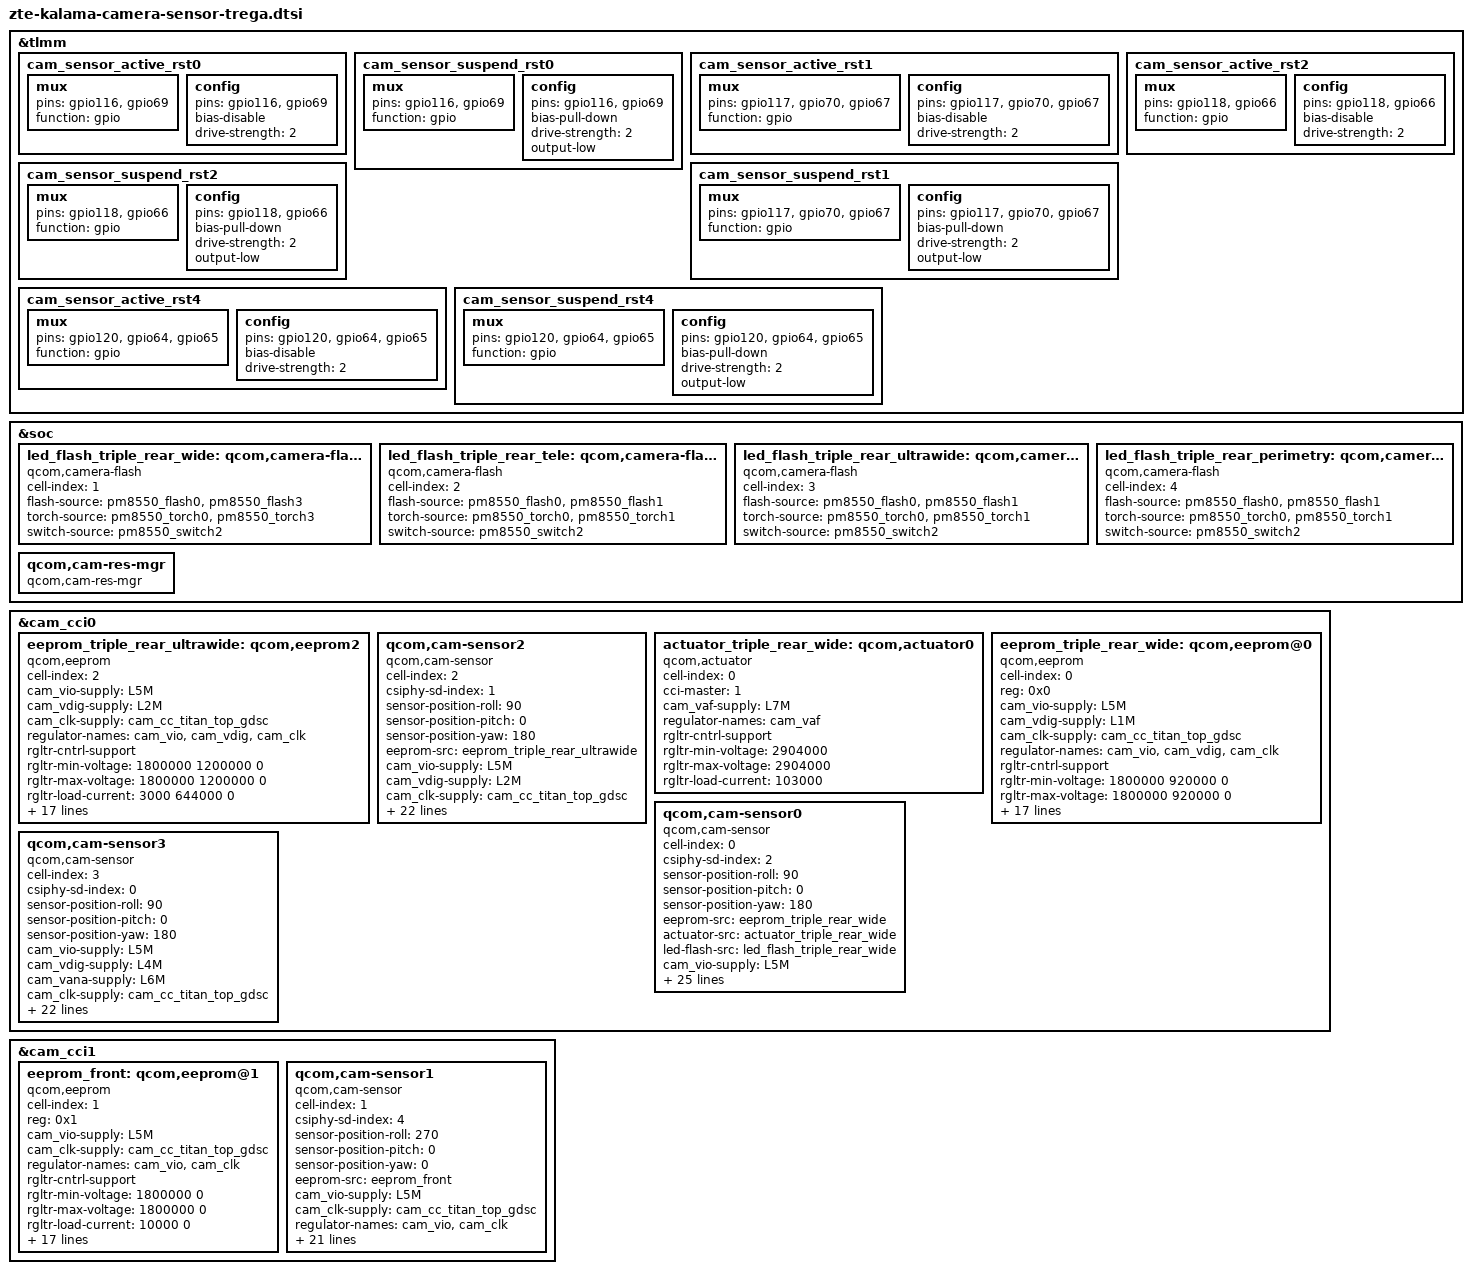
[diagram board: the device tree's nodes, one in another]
#include <dt-bindings/msm-camera.h>
&tlmm {
	cam_sensor_active_rst0: cam_sensor_active_rst0 {
		/* RESET 2 */
		mux {
			pins = "gpio116", "gpio69";
			function = "gpio";
		};

		config {
			pins = "gpio116", "gpio69";
			bias-disable; /* No PULL */
			drive-strength = <2>; /* 2 MA */
		};
	};

	cam_sensor_suspend_rst0: cam_sensor_suspend_rst0 {
		/* RESET 2 */
		mux {
			pins = "gpio116", "gpio69";
			function = "gpio";
		};

		config {
			pins = "gpio116", "gpio69";
			bias-pull-down; /* PULL DOWN */
			drive-strength = <2>; /* 2 MA */
			output-low;
		};
	};

	cam_sensor_active_rst1: cam_sensor_active_rst1 {
		/* RESET 2 */
		mux {
			pins = "gpio117", "gpio70", "gpio67";
			function = "gpio";
		};

		config {
			pins = "gpio117", "gpio70", "gpio67";
			bias-disable; /* No PULL */
			drive-strength = <2>; /* 2 MA */
		};
	};

	cam_sensor_suspend_rst1: cam_sensor_suspend_rst1 {
		/* RESET 2 */
		mux {
			pins = "gpio117", "gpio70", "gpio67";
			function = "gpio";
		};

		config {
			pins = "gpio117", "gpio70", "gpio67";
			bias-pull-down; /* PULL DOWN */
			drive-strength = <2>; /* 2 MA */
			output-low;
		};
	};

	cam_sensor_active_rst2: cam_sensor_active_rst2 {
		/* RESET 2 */
		mux {
			pins = "gpio118", "gpio66";
			function = "gpio";
		};

		config {
			pins = "gpio118", "gpio66";
			bias-disable; /* No PULL */
			drive-strength = <2>; /* 2 MA */
		};
	};

	cam_sensor_suspend_rst2: cam_sensor_suspend_rst2 {
		/* RESET 2 */
		mux {
			pins = "gpio118", "gpio66";
			function = "gpio";
		};

		config {
			pins = "gpio118", "gpio66";
			bias-pull-down; /* PULL DOWN */
			drive-strength = <2>; /* 2 MA */
			output-low;
		};
	};

	cam_sensor_active_rst4: cam_sensor_active_rst4 {
		/* RESET 3 */
		mux {
			pins = "gpio120", "gpio64", "gpio65";
			function = "gpio";
		};

		config {
			pins = "gpio120", "gpio64", "gpio65";
			bias-disable; /* No PULL */
			drive-strength = <2>; /* 2 MA */
		};
	};

	cam_sensor_suspend_rst4: cam_sensor_suspend_rst4 {
		/* RESET 3 */
		mux {
			pins = "gpio120", "gpio64", "gpio65";
			function = "gpio";
		};

		config {
			pins = "gpio120", "gpio64", "gpio65";
			bias-pull-down; /* PULL DOWN */
			drive-strength = <2>; /* 2 MA */
			output-low;
		};
	};
};

&soc {
	led_flash_triple_rear_wide: qcom,camera-flash1 {
		cell-index = <1>;
		compatible = "qcom,camera-flash";
		flash-source = <&pm8550_flash0 &pm8550_flash3>;
		torch-source = <&pm8550_torch0 &pm8550_torch3>;
		switch-source = <&pm8550_switch2>;
		status = "ok";
	};

	led_flash_triple_rear_tele: qcom,camera-flash2 {
		cell-index = <2>;
		compatible = "qcom,camera-flash";
		flash-source = <&pm8550_flash0 &pm8550_flash1>;
		torch-source = <&pm8550_torch0 &pm8550_torch1>;
		switch-source = <&pm8550_switch2>;
		status = "ok";
	};

	led_flash_triple_rear_ultrawide: qcom,camera-flash3 {
		cell-index = <3>;
		compatible = "qcom,camera-flash";
		flash-source = <&pm8550_flash0 &pm8550_flash1>;
		torch-source = <&pm8550_torch0 &pm8550_torch1>;
		switch-source = <&pm8550_switch2>;
		status = "ok";
	};

	led_flash_triple_rear_perimetry: qcom,camera-flash4 {
		cell-index = <4>;
		compatible = "qcom,camera-flash";
		flash-source = <&pm8550_flash0 &pm8550_flash1>;
		torch-source = <&pm8550_torch0 &pm8550_torch1>;
		switch-source = <&pm8550_switch2>;
		status = "ok";
	};

	qcom,cam-res-mgr {
		compatible = "qcom,cam-res-mgr";
		status = "ok";
	};
};

&cam_cci0 {
	/delete-node/ actuator_triple_uw;
	/delete-node/ actuator_triple_wide;
	/delete-node/ actuator_ois;
	/delete-node/ actuator_hp1;
	/delete-node/ ois0;
	/delete-node/ eeprom_tof1;
	/delete-node/ eeprom_uw;
	/delete-node/ eeprom_wide;
	/delete-node/ eeprom_ois;
	/delete-node/ eeprom_hp1;
	/delete-node/ qcom,cam-sensor7;
	/delete-node/ qcom,cam-sensor1;
	/delete-node/ qcom,cam-sensor2;
	/delete-node/ qcom,cam-sensor9;
	/delete-node/ qcom,cam-sensor0;
//8Mback
    eeprom_triple_rear_ultrawide: qcom,eeprom2 {
	    cell-index = <2>;
	    compatible = "qcom,eeprom";
		cam_vio-supply = <&L5M>;
		cam_vdig-supply = <&L2M>;
		cam_clk-supply = <&cam_cc_titan_top_gdsc>;
		regulator-names = "cam_vio", "cam_vdig", "cam_clk";
		rgltr-cntrl-support;
		rgltr-min-voltage = <1800000 1200000 0>;
		rgltr-max-voltage = <1800000 1200000 0>;
		rgltr-load-current = <3000 644000 0>;
		gpio-no-mux = <0>;
		pinctrl-names = "cam_default", "cam_suspend";
		pinctrl-0 = <&cam_sensor_mclk1_active
				 &cam_sensor_active_rst1>;
		pinctrl-1 = <&cam_sensor_mclk1_suspend
				 &cam_sensor_suspend_rst1>;
		gpios = <&tlmm 101 0>,
			<&tlmm 117 0>,
			<&tlmm 70 0>,
			<&tlmm 67 0>;
		gpio-reset = <1>;
		gpio-standby = <2>;
		gpio-custom1 = <3>;
		gpio-req-tbl-num = <0 1 2 3>;
		gpio-req-tbl-flags = <1 0 0 0>;
		gpio-req-tbl-label = "CAMIF_MCLK1",
							 "CAM_RESET1",
							 "CAM_STANDBY1",
							 "CAM_VANA1";
		cci-master = <CCI_MASTER_0>;
		clocks = <&camcc CAM_CC_MCLK1_CLK>;
		clock-names = "cam_clk";
		clock-cntl-level = "nominal";
		clock-rates = <19200000>;
		status = "ok";
    };

	qcom,cam-sensor2 {
		cell-index = <2>;
		compatible = "qcom,cam-sensor";
		csiphy-sd-index = <1>;
		sensor-position-roll = <90>;
		sensor-position-pitch = <0>;
		sensor-position-yaw = <180>;
		eeprom-src = <&eeprom_triple_rear_ultrawide>;
		cam_vio-supply = <&L5M>;
		cam_vdig-supply = <&L2M>;
		cam_clk-supply = <&cam_cc_titan_top_gdsc>;
		regulator-names = "cam_vio", "cam_vdig", "cam_clk";
		rgltr-cntrl-support;
		rgltr-min-voltage = <1800000 1200000 0>;
		rgltr-max-voltage = <1800000 1200000 0>;
		rgltr-load-current = <3000 644000 0>;
		gpio-no-mux = <0>;
		pinctrl-names = "cam_default", "cam_suspend";
		pinctrl-0 = <&cam_sensor_mclk1_active
				 &cam_sensor_active_rst1>;
		pinctrl-1 = <&cam_sensor_mclk1_suspend
				 &cam_sensor_suspend_rst1>;
		gpios = <&tlmm 101 0>,
			<&tlmm 117 0>,
			<&tlmm 70 0>,
			<&tlmm 67 0>;
		gpio-reset = <1>;
		gpio-standby = <2>;
		gpio-custom1 = <3>;
		gpio-req-tbl-num = <0 1 2 3>;
		gpio-req-tbl-flags = <1 0 0 0>;
		gpio-req-tbl-label = "CAMIF_MCLK1",
							 "CAM_RESET1",
							 "CAM_STANDBY1",
							 "CAM_VANA1";
		cci-master = <CCI_MASTER_0>;
		clocks = <&camcc CAM_CC_MCLK1_CLK>;
		clock-names = "cam_clk";
		clock-cntl-level = "nominal";
		clock-rates = <19200000>;
		status = "ok";
	};

//main
	actuator_triple_rear_wide: qcom,actuator0 {
		cell-index = <0>;
		compatible = "qcom,actuator";
		cci-master = <1>;
		cam_vaf-supply = <&L7M>;
		regulator-names = "cam_vaf";
		rgltr-cntrl-support;
		rgltr-min-voltage = <2904000>;
		rgltr-max-voltage = <2904000>;
		rgltr-load-current = <103000>;
		status = "ok";
	};

	eeprom_triple_rear_wide: qcom,eeprom@0 {
		cell-index = <0>;
		compatible = "qcom,eeprom";
		reg = <0x0>;
		cam_vio-supply = <&L5M>;
		cam_vdig-supply = <&L1M>;
		cam_clk-supply = <&cam_cc_titan_top_gdsc>;
		regulator-names = "cam_vio", "cam_vdig", "cam_clk";
		rgltr-cntrl-support;
		rgltr-min-voltage = <1800000 920000 0>;
		rgltr-max-voltage = <1800000 920000 0>;
		rgltr-load-current = <3500 140000 0>;
		gpio-no-mux = <0>;
		pinctrl-names = "cam_default", "cam_suspend";
		pinctrl-0 = <&cam_sensor_mclk2_active
				 &cam_sensor_active_rst2>;
		pinctrl-1 = <&cam_sensor_mclk2_suspend
				 &cam_sensor_suspend_rst2>;
		gpios = <&tlmm 102 0>,
			<&tlmm 118 0>,
			<&tlmm 66 0>;
		gpio-reset = <1>;
		gpio-custom1 = <2>;
		gpio-req-tbl-num = <0 1 2>;
		gpio-req-tbl-flags = <1 0 0>;
		gpio-req-tbl-label = "CAMIF_MCLK2",
					"CAM_RESET2",
					"CAM_VANA2";
		cci-master = <CCI_MASTER_1>;
		clocks = <&camcc CAM_CC_MCLK2_CLK>;
		clock-names = "cam_clk";
		clock-cntl-level = "nominal";
		clock-rates = <19200000>;
		status = "ok";
	};

	qcom,cam-sensor0 {
		cell-index = <0>;
		compatible = "qcom,cam-sensor";
		csiphy-sd-index = <2>;
		sensor-position-roll = <90>;
		sensor-position-pitch = <0>;
		sensor-position-yaw = <180>;
		eeprom-src = <&eeprom_triple_rear_wide>;
		actuator-src = <&actuator_triple_rear_wide>;
		led-flash-src = <&led_flash_triple_rear_wide>;
		cam_vio-supply = <&L5M>;
		cam_vdig-supply = <&L1M>;
		cam_vaf-supply = <&L7M>;
		cam_clk-supply = <&cam_cc_titan_top_gdsc>;
		regulator-names = "cam_vio", "cam_vdig", "cam_vaf", "cam_clk";
		rgltr-cntrl-support;
		rgltr-min-voltage = <1800000 920000 2904000 0>;
		rgltr-max-voltage = <1800000 920000 2904000 0>;
		rgltr-load-current = <3500 140000 103000 0>;
		gpio-no-mux = <0>;
		pinctrl-names = "cam_default", "cam_suspend";
		pinctrl-0 = <&cam_sensor_mclk2_active
				 &cam_sensor_active_rst2>;
		pinctrl-1 = <&cam_sensor_mclk2_suspend
				 &cam_sensor_suspend_rst2>;
		gpios = <&tlmm 102 0>,
			<&tlmm 118 0>,
			<&tlmm 66 0>;
		gpio-reset = <1>;
		gpio-custom1 = <2>;
		gpio-req-tbl-num = <0 1 2>;
		gpio-req-tbl-flags = <1 0 0>;
		gpio-req-tbl-label = "CAMIF_MCLK2",
					"CAM_RESET2",
					"CAM_VANA2";
		cci-master = <CCI_MASTER_1>;
		clocks = <&camcc CAM_CC_MCLK2_CLK>;
		clock-names = "cam_clk";
		clock-cntl-level = "nominal";
		clock-rates = <19200000>;
		status = "ok";
	};

//2M
	qcom,cam-sensor3 {
		cell-index = <3>;
		compatible = "qcom,cam-sensor";
		csiphy-sd-index = <0>;
		sensor-position-roll = <90>;
		sensor-position-pitch = <0>;
		sensor-position-yaw = <180>;
		cam_vio-supply = <&L5M>;
		cam_vdig-supply = <&L4M>;
		cam_vana-supply = <&L6M>;
		cam_clk-supply = <&cam_cc_titan_top_gdsc>;
		regulator-names = "cam_vio", "cam_vdig", "cam_vana", "cam_clk";
		rgltr-cntrl-support;
		rgltr-min-voltage = <1800000 1800000 2800000 0>;
		rgltr-max-voltage = <1800000 1800000 2800000 0>;
		rgltr-load-current = <3500 3500 52000 0>;
		gpio-no-mux = <0>;
		pinctrl-names = "cam_default", "cam_suspend";
		pinctrl-0 = <&cam_sensor_mclk0_active
				 &cam_sensor_active_rst0>;
		pinctrl-1 = <&cam_sensor_mclk0_suspend
				 &cam_sensor_suspend_rst0>;
		gpios = <&tlmm 100 0>,
			<&tlmm 116 0>,
			<&tlmm 69 0>;
		gpio-reset = <1>;
		gpio-custom1 = <2>;
		gpio-req-tbl-num = <0 1 2>;
		gpio-req-tbl-flags = <1 0 0>;
		gpio-req-tbl-label = "CAMIF_MCLK0",
					"CAM_RESET0",
					"CAM_VANA0";
		cci-master = <CCI_MASTER_0>;
		clocks = <&camcc CAM_CC_MCLK0_CLK>;
		clock-names = "cam_clk";
		clock-cntl-level = "nominal";
		clock-rates = <24000000>;
		status = "ok";
	};
};

&cam_cci1 {
	/delete-node/ actuator_triple_tele;
	/delete-node/ eeprom_tele;
	/delete-node/ eeprom_aon_front;
	/delete-node/ qcom,cam-sensor3;
	/delete-node/ qcom,cam-sensor4;
//front
	eeprom_front: qcom,eeprom@1 {
		cell-index = <1>;
		compatible = "qcom,eeprom";
		reg = <0x1>;
		cam_vio-supply = <&L5M>;
		cam_clk-supply = <&cam_cc_titan_top_gdsc>;
		regulator-names = "cam_vio", "cam_clk";
		rgltr-cntrl-support;
		rgltr-min-voltage = <1800000 0>;
		rgltr-max-voltage = <1800000 0>;
		rgltr-load-current = <10000 0>;
		gpio-no-mux = <0>;
		pinctrl-names = "cam_default", "cam_suspend";
		pinctrl-0 = <&cam_sensor_mclk4_active
				 &cam_sensor_active_rst4>;
		pinctrl-1 = <&cam_sensor_mclk4_suspend
				 &cam_sensor_suspend_rst4>;
		gpios = <&tlmm 104 0>,
			<&tlmm 120 0>,
			<&tlmm 64 0>,
			<&tlmm 65 0>;
		gpio-reset = <1>;
		gpio-custom1 = <2>;
		gpio-standby = <3>;
		gpio-req-tbl-num = <0 1 2 3>;
		gpio-req-tbl-flags = <1 0 0 0>;
		gpio-req-tbl-label = "CAMIF_MCLK4",
					"CAM_RESET4",
					"CAM_VANA4",
					"CAM_STANDBY5";
		cci-master = <CCI_MASTER_0>;
		clocks = <&camcc CAM_CC_MCLK4_CLK>;
		clock-names = "cam_clk";
		clock-cntl-level = "nominal";
		clock-rates = <24000000>;
		status = "ok";
	};


	qcom,cam-sensor1 {
		cell-index = <1>;
		compatible = "qcom,cam-sensor";
		csiphy-sd-index = <4>;
		sensor-position-roll = <270>;
		sensor-position-pitch = <0>;
		sensor-position-yaw = <0>;
		eeprom-src = <&eeprom_front>;
		cam_vio-supply = <&L5M>;
		cam_clk-supply = <&cam_cc_titan_top_gdsc>;
		regulator-names = "cam_vio", "cam_clk";
		rgltr-cntrl-support;
		rgltr-min-voltage = <1800000 0>;
		rgltr-max-voltage = <1800000 0>;
		rgltr-load-current = <10000 0>;
		gpio-no-mux = <0>;
		pinctrl-names = "cam_default", "cam_suspend";
		pinctrl-0 = <&cam_sensor_mclk4_active
				 &cam_sensor_active_rst4>;
		pinctrl-1 = <&cam_sensor_mclk4_suspend
				 &cam_sensor_suspend_rst4>;
		gpios = <&tlmm 104 0>,
			<&tlmm 120 0>,
			<&tlmm 64 0>,
			<&tlmm 65 0>;
		gpio-reset = <1>;
		gpio-custom1 = <2>;
		gpio-standby = <3>;
		gpio-req-tbl-num = <0 1 2 3>;
		gpio-req-tbl-flags = <1 0 0 0>;
		gpio-req-tbl-label = "CAMIF_MCLK4",
					"CAM_RESET4",
					"CAM_VANA4",
					"CAM_STANDBY5";
		cci-master = <CCI_MASTER_0>;
		clocks = <&camcc CAM_CC_MCLK4_CLK>;
		clock-names = "cam_clk";
		clock-cntl-level = "nominal";
		clock-rates = <24000000>;
		status = "ok";
	};
};
